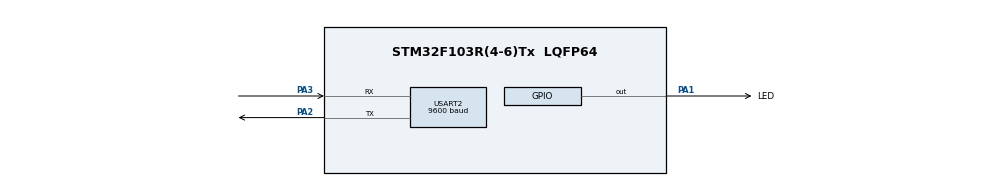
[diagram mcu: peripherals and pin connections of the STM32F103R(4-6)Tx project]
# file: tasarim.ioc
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Mcu.Family=STM32F1
Mcu.Name=STM32F103R(4-6)Tx
Mcu.Package=LQFP64
NVIC.PriorityGroup=NVIC_PRIORITYGROUP_4
NVIC.USART2_IRQn=true\:0\:0\:false\:false\:true\:true\:true\:true
PA1.GPIO_Label=LED
PA1.GPIO_Speed=GPIO_SPEED_FREQ_LOW
PA1.Signal=GPIO_Output
PA2.Mode=Asynchronous
PA2.Signal=USART2_TX
PA3.Mode=Asynchronous
PA3.Signal=USART2_RX
PD0-OSC_IN.Mode=HSE-External-Oscillator
PD0-OSC_IN.Signal=RCC_OSC_IN
PD1-OSC_OUT.Mode=HSE-External-Oscillator
PD1-OSC_OUT.Signal=RCC_OSC_OUT
ProjectManager.HeapSize=0x200
ProjectManager.StackSize=0x400
ProjectManager.TargetToolchain=STM32CubeIDE
RCC.APB1Freq_Value=8000000
RCC.APB2Freq_Value=8000000
USART2.BaudRate=9600
USART2.VirtualMode=VM_ASYNC
VP_SYS_VS_ND.Mode=No_Debug
board=custom

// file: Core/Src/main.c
/* USER CODE BEGIN Header */
/**
  ******************************************************************************
  * @file           : main.c
  * @brief          : UART command processor and LED control application
  ******************************************************************************
  */
/* USER CODE END Header */

#include "main.h"

/* USER CODE BEGIN Includes */
#include "led_app.h"
#include "uart_transport.h"
/* USER CODE END Includes */

UART_HandleTypeDef huart2;

/* USER CODE BEGIN PV */
static LedApp led_app;
/* USER CODE END PV */

void SystemClock_Config(void);
static void MX_GPIO_Init(void);
static void MX_USART2_UART_Init(void);

/* USER CODE BEGIN 0 */
static void App_WriteLed(void *context, bool led_on)
{
  (void)context;
  HAL_GPIO_WritePin(LED_GPIO_Port, LED_Pin,
                    led_on ? GPIO_PIN_SET : GPIO_PIN_RESET);
}
/* USER CODE END 0 */

int main(void)
{
  /* USER CODE BEGIN 1 */
  const LedAppIo app_io = {
    .write_led = App_WriteLed,
    .write_uart = UartTransport_Queue,
    .context = NULL
  };
  /* USER CODE END 1 */

  HAL_Init();
  SystemClock_Config();

  MX_GPIO_Init();
  MX_USART2_UART_Init();

  /* USER CODE BEGIN 2 */
  LedApp_Init(&led_app, &app_io, HAL_GetTick());
  if (UartTransport_Init(&huart2, &led_app) != HAL_OK)
  {
    Error_Handler();
  }
  /* USER CODE END 2 */

  while (1)
  {

    /* USER CODE BEGIN 3 */
    LedApp_Process(&led_app, HAL_GetTick());
    UartTransport_Poll();
  }
  /* USER CODE END 3 */
}

void SystemClock_Config(void)
{
  RCC_OscInitTypeDef RCC_OscInitStruct = {0};
  RCC_ClkInitTypeDef RCC_ClkInitStruct = {0};

  RCC_OscInitStruct.OscillatorType = RCC_OSCILLATORTYPE_HSI;
  RCC_OscInitStruct.HSIState = RCC_HSI_ON;
  RCC_OscInitStruct.HSICalibrationValue = RCC_HSICALIBRATION_DEFAULT;
  RCC_OscInitStruct.PLL.PLLState = RCC_PLL_NONE;
  if (HAL_RCC_OscConfig(&RCC_OscInitStruct) != HAL_OK)
  {
    Error_Handler();
  }

  RCC_ClkInitStruct.ClockType = RCC_CLOCKTYPE_HCLK | RCC_CLOCKTYPE_SYSCLK |
                                RCC_CLOCKTYPE_PCLK1 | RCC_CLOCKTYPE_PCLK2;
  RCC_ClkInitStruct.SYSCLKSource = RCC_SYSCLKSOURCE_HSI;
  RCC_ClkInitStruct.AHBCLKDivider = RCC_SYSCLK_DIV1;
  RCC_ClkInitStruct.APB1CLKDivider = RCC_HCLK_DIV1;
  RCC_ClkInitStruct.APB2CLKDivider = RCC_HCLK_DIV1;

  if (HAL_RCC_ClockConfig(&RCC_ClkInitStruct, FLASH_LATENCY_0) != HAL_OK)
  {
    Error_Handler();
  }
}

static void MX_USART2_UART_Init(void)
{
  huart2.Instance = USART2;
  huart2.Init.BaudRate = 9600;
  huart2.Init.WordLength = UART_WORDLENGTH_8B;
  huart2.Init.StopBits = UART_STOPBITS_1;
  huart2.Init.Parity = UART_PARITY_NONE;
  huart2.Init.Mode = UART_MODE_TX_RX;
  huart2.Init.HwFlowCtl = UART_HWCONTROL_NONE;
  huart2.Init.OverSampling = UART_OVERSAMPLING_16;
  if (HAL_UART_Init(&huart2) != HAL_OK)
  {
    Error_Handler();
  }
}

static void MX_GPIO_Init(void)
{
  GPIO_InitTypeDef GPIO_InitStruct = {0};

  __HAL_RCC_GPIOA_CLK_ENABLE();

  HAL_GPIO_WritePin(LED_GPIO_Port, LED_Pin, GPIO_PIN_RESET);

  GPIO_InitStruct.Pin = LED_Pin;
  GPIO_InitStruct.Mode = GPIO_MODE_OUTPUT_PP;
  GPIO_InitStruct.Speed = GPIO_SPEED_FREQ_LOW;
  HAL_GPIO_Init(LED_GPIO_Port, &GPIO_InitStruct);
}

void Error_Handler(void)
{
  __disable_irq();
  while (1)
  {
  }
}
